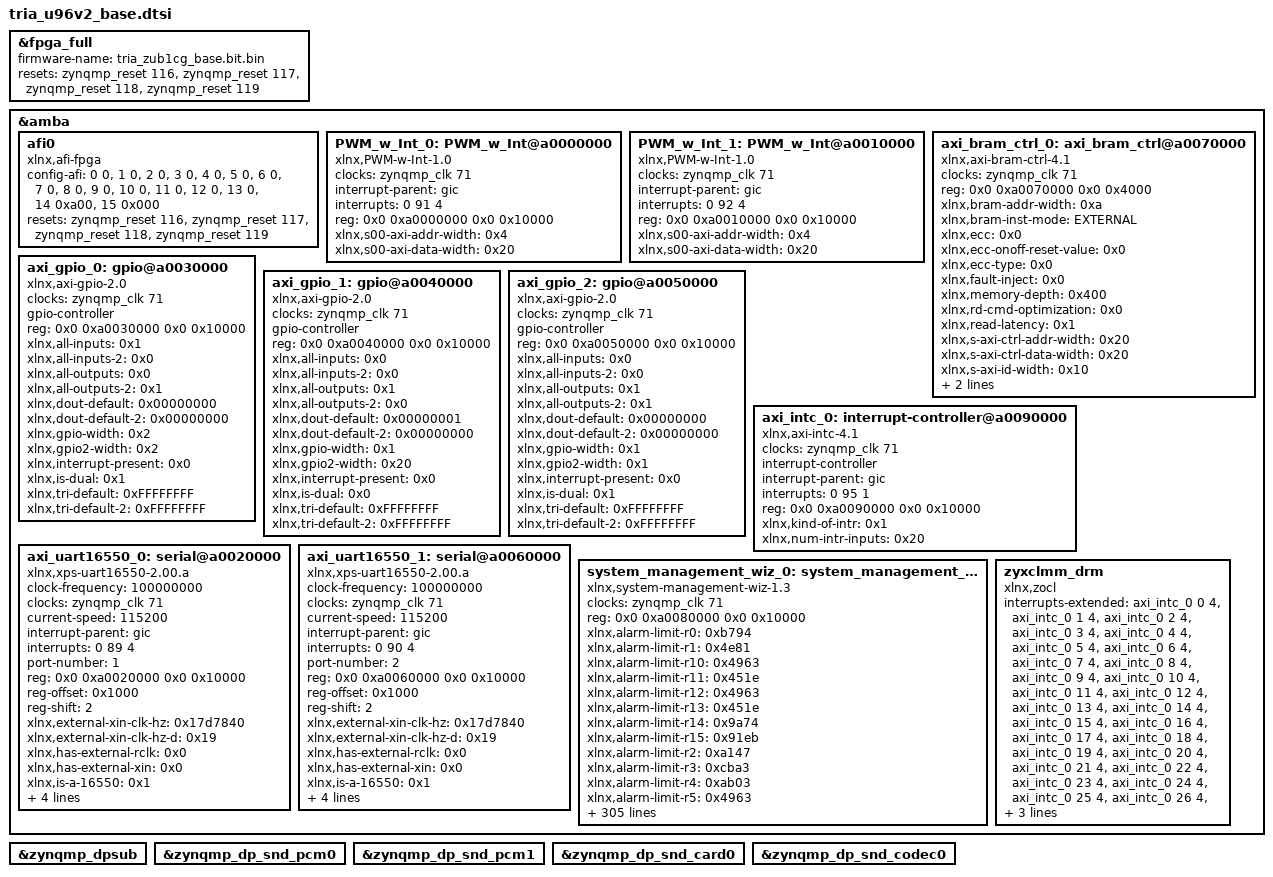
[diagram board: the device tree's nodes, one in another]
/dts-v1/;
/plugin/;

#include <dt-bindings/gpio/gpio.h>

&fpga_full {	
	#address-cells = <2>;
	#size-cells = <2>;
	firmware-name = "tria_zub1cg_base.bit.bin";
	resets = <&zynqmp_reset 116>, <&zynqmp_reset 117>, <&zynqmp_reset 118>, <&zynqmp_reset 119>;
};

&amba {
	afi0: afi0 {
		compatible = "xlnx,afi-fpga";
		config-afi = <0 0>, <1 0>, <2 0>, <3 0>, <4 0>, <5 0>, <6 0>, <7 0>, <8 0>, <9 0>, <10 0>, <11 0>, <12 0>, <13 0>, <14 0xa00>, <15 0x000>;
		resets = <&zynqmp_reset 116>, <&zynqmp_reset 117>, <&zynqmp_reset 118>, <&zynqmp_reset 119>;
		reset-names = "pl0", "pl1", "pl2", "pl3";
	};		
};

&amba {		
		PWM_w_Int_0: PWM_w_Int@a0000000 {
			clock-names = "s00_axi_aclk";
			clocks = <&zynqmp_clk 71>;
			compatible = "xlnx,PWM-w-Int-1.0";
			interrupt-names = "Interrupt_Out";
			interrupt-parent = <&gic>;
			interrupts = <0 91 4>;
			reg = <0x0 0xa0000000 0x0 0x10000>;
			xlnx,s00-axi-addr-width = <0x4>;
			xlnx,s00-axi-data-width = <0x20>;
		};
		PWM_w_Int_1: PWM_w_Int@a0010000 {
			clock-names = "s00_axi_aclk";
			clocks = <&zynqmp_clk 71>;
			compatible = "xlnx,PWM-w-Int-1.0";
			interrupt-names = "Interrupt_Out";
			interrupt-parent = <&gic>;
			interrupts = <0 92 4>;
			reg = <0x0 0xa0010000 0x0 0x10000>;
			xlnx,s00-axi-addr-width = <0x4>;
			xlnx,s00-axi-data-width = <0x20>;
		};
		axi_bram_ctrl_0: axi_bram_ctrl@a0070000 {
			clock-names = "s_axi_aclk";
			clocks = <&zynqmp_clk 71>;
			compatible = "xlnx,axi-bram-ctrl-4.1";
			reg = <0x0 0xa0070000 0x0 0x4000>;
			xlnx,bram-addr-width = <0xa>;
			xlnx,bram-inst-mode = "EXTERNAL";
			xlnx,ecc = <0x0>;
			xlnx,ecc-onoff-reset-value = <0x0>;
			xlnx,ecc-type = <0x0>;
			xlnx,fault-inject = <0x0>;
			xlnx,memory-depth = <0x400>;
			xlnx,rd-cmd-optimization = <0x0>;
			xlnx,read-latency = <0x1>;
			xlnx,s-axi-ctrl-addr-width = <0x20>;
			xlnx,s-axi-ctrl-data-width = <0x20>;
			xlnx,s-axi-id-width = <0x10>;
			xlnx,s-axi-supports-narrow-burst = <0x1>;
			xlnx,single-port-bram = <0x0>;
		};
		axi_gpio_0: gpio@a0030000 {
			#gpio-cells = <2>;
			clock-names = "s_axi_aclk";
			clocks = <&zynqmp_clk 71>;
			compatible = "xlnx,axi-gpio-2.0", "xlnx,xps-gpio-1.00.a";
			gpio-controller ;
			reg = <0x0 0xa0030000 0x0 0x10000>;
			xlnx,all-inputs = <0x1>;
			xlnx,all-inputs-2 = <0x0>;
			xlnx,all-outputs = <0x0>;
			xlnx,all-outputs-2 = <0x1>;
			xlnx,dout-default = <0x00000000>;
			xlnx,dout-default-2 = <0x00000000>;
			xlnx,gpio-width = <0x2>;
			xlnx,gpio2-width = <0x2>;
			xlnx,interrupt-present = <0x0>;
			xlnx,is-dual = <0x1>;
			xlnx,tri-default = <0xFFFFFFFF>;
			xlnx,tri-default-2 = <0xFFFFFFFF>;
		};
		axi_gpio_1: gpio@a0040000 {
			#gpio-cells = <2>;
			clock-names = "s_axi_aclk";
			clocks = <&zynqmp_clk 71>;
			compatible = "xlnx,axi-gpio-2.0", "xlnx,xps-gpio-1.00.a";
			gpio-controller ;
			reg = <0x0 0xa0040000 0x0 0x10000>;
			xlnx,all-inputs = <0x0>;
			xlnx,all-inputs-2 = <0x0>;
			xlnx,all-outputs = <0x1>;
			xlnx,all-outputs-2 = <0x0>;
			xlnx,dout-default = <0x00000001>;
			xlnx,dout-default-2 = <0x00000000>;
			xlnx,gpio-width = <0x1>;
			xlnx,gpio2-width = <0x20>;
			xlnx,interrupt-present = <0x0>;
			xlnx,is-dual = <0x0>;
			xlnx,tri-default = <0xFFFFFFFF>;
			xlnx,tri-default-2 = <0xFFFFFFFF>;
		};
		axi_gpio_2: gpio@a0050000 {
			#gpio-cells = <2>;
			clock-names = "s_axi_aclk";
			clocks = <&zynqmp_clk 71>;
			compatible = "xlnx,axi-gpio-2.0", "xlnx,xps-gpio-1.00.a";
			gpio-controller ;
			reg = <0x0 0xa0050000 0x0 0x10000>;
			xlnx,all-inputs = <0x0>;
			xlnx,all-inputs-2 = <0x0>;
			xlnx,all-outputs = <0x1>;
			xlnx,all-outputs-2 = <0x1>;
			xlnx,dout-default = <0x00000000>;
			xlnx,dout-default-2 = <0x00000000>;
			xlnx,gpio-width = <0x1>;
			xlnx,gpio2-width = <0x1>;
			xlnx,interrupt-present = <0x0>;
			xlnx,is-dual = <0x1>;
			xlnx,tri-default = <0xFFFFFFFF>;
			xlnx,tri-default-2 = <0xFFFFFFFF>;
		};
		axi_intc_0: interrupt-controller@a0090000 {
			#interrupt-cells = <2>;
			clock-names = "s_axi_aclk";
			clocks = <&zynqmp_clk 71>;
			compatible = "xlnx,axi-intc-4.1", "xlnx,xps-intc-1.00.a";
			interrupt-controller ;
			interrupt-names = "irq";
			interrupt-parent = <&gic>;
			interrupts = <0 95 1>;
			reg = <0x0 0xa0090000 0x0 0x10000>;
			xlnx,kind-of-intr = <0x1>;
			xlnx,num-intr-inputs = <0x20>;
		};
		axi_uart16550_0: serial@a0020000 {
			clock-frequency = <100000000>;
			clock-names = "s_axi_aclk";
			clocks = <&zynqmp_clk 71>;
			compatible = "xlnx,xps-uart16550-2.00.a", "ns16550a";
			current-speed = <115200>;
			device_type = "serial";
			interrupt-names = "ip2intc_irpt";
			interrupt-parent = <&gic>;
			interrupts = <0 89 4>;
			port-number = <1>;
			reg = <0x0 0xa0020000 0x0 0x10000>;
			reg-offset = <0x1000>;
			reg-shift = <2>;
			xlnx,external-xin-clk-hz = <0x17d7840>;
			xlnx,external-xin-clk-hz-d = <0x19>;
			xlnx,has-external-rclk = <0x0>;
			xlnx,has-external-xin = <0x0>;
			xlnx,is-a-16550 = <0x1>;
			xlnx,s-axi-aclk-freq-hz-d = "100.0";
			xlnx,sim-device = "VERSAL_AI_CORE_ES1";
			xlnx,use-modem-ports = <0x1>;
			xlnx,use-user-ports = <0x1>;
		};
		axi_uart16550_1: serial@a0060000 {
			clock-frequency = <100000000>;
			clock-names = "s_axi_aclk";
			clocks = <&zynqmp_clk 71>;
			compatible = "xlnx,xps-uart16550-2.00.a", "ns16550a";
			current-speed = <115200>;
			device_type = "serial";
			interrupt-names = "ip2intc_irpt";
			interrupt-parent = <&gic>;
			interrupts = <0 90 4>;
			port-number = <2>;
			reg = <0x0 0xa0060000 0x0 0x10000>;
			reg-offset = <0x1000>;
			reg-shift = <2>;
			xlnx,external-xin-clk-hz = <0x17d7840>;
			xlnx,external-xin-clk-hz-d = <0x19>;
			xlnx,has-external-rclk = <0x0>;
			xlnx,has-external-xin = <0x0>;
			xlnx,is-a-16550 = <0x1>;
			xlnx,s-axi-aclk-freq-hz-d = "100.0";
			xlnx,sim-device = "VERSAL_AI_CORE_ES1";
			xlnx,use-modem-ports = <0x1>;
			xlnx,use-user-ports = <0x1>;
		};
		system_management_wiz_0: system_management_wiz@a0080000 {
			clock-names = "s_axi_aclk";
			clocks = <&zynqmp_clk 71>;
			compatible = "xlnx,system-management-wiz-1.3";
			reg = <0x0 0xa0080000 0x0 0x10000>;
			xlnx,alarm-limit-r0 = <0xb794>;
			xlnx,alarm-limit-r1 = <0x4e81>;
			xlnx,alarm-limit-r10 = <0x4963>;
			xlnx,alarm-limit-r11 = <0x451e>;
			xlnx,alarm-limit-r12 = <0x4963>;
			xlnx,alarm-limit-r13 = <0x451e>;
			xlnx,alarm-limit-r14 = <0x9a74>;
			xlnx,alarm-limit-r15 = <0x91eb>;
			xlnx,alarm-limit-r2 = <0xa147>;
			xlnx,alarm-limit-r3 = <0xcba3>;
			xlnx,alarm-limit-r4 = <0xab03>;
			xlnx,alarm-limit-r5 = <0x4963>;
			xlnx,alarm-limit-r6 = <0x9555>;
			xlnx,alarm-limit-r7 = <0xb00a>;
			xlnx,alarm-limit-r8 = <0x4e81>;
			xlnx,alarm-limit-r9 = <0x4963>;
			xlnx,alarm-limit-slave0-ssit-usl1 = <0x4c5e>;
			xlnx,alarm-limit-slave0-ssit-usl2 = <0x4bf2>;
			xlnx,alarm-limit-slave0-ssit-usl3 = <0x98bf>;
			xlnx,alarm-limit-slave0-ssit-usl4 = <0x98bf>;
			xlnx,alarm-limit-slave0-ssit-usu1 = <0x4d39>;
			xlnx,alarm-limit-slave0-ssit-usu2 = <0x4da7>;
			xlnx,alarm-limit-slave0-ssit-usu3 = <0x9a74>;
			xlnx,alarm-limit-slave0-ssit-usu4 = <0x9a74>;
			xlnx,alarm-limit-slave1-ssit-usl1 = <0x4c5e>;
			xlnx,alarm-limit-slave1-ssit-usl2 = <0x4bf2>;
			xlnx,alarm-limit-slave1-ssit-usl3 = <0x98bf>;
			xlnx,alarm-limit-slave1-ssit-usl4 = <0x98bf>;
			xlnx,alarm-limit-slave1-ssit-usu1 = <0x4d39>;
			xlnx,alarm-limit-slave1-ssit-usu2 = <0x4da7>;
			xlnx,alarm-limit-slave1-ssit-usu3 = <0x9a74>;
			xlnx,alarm-limit-slave1-ssit-usu4 = <0x9a74>;
			xlnx,alarm-limit-slave2-ssit-usl1 = <0x4c5e>;
			xlnx,alarm-limit-slave2-ssit-usl2 = <0x4bf2>;
			xlnx,alarm-limit-slave2-ssit-usl3 = <0x98bf>;
			xlnx,alarm-limit-slave2-ssit-usl4 = <0x98bf>;
			xlnx,alarm-limit-slave2-ssit-usu1 = <0x4d39>;
			xlnx,alarm-limit-slave2-ssit-usu2 = <0x4da7>;
			xlnx,alarm-limit-slave2-ssit-usu3 = <0x9a74>;
			xlnx,alarm-limit-slave2-ssit-usu4 = <0x9a74>;
			xlnx,alarm-limit-usl1 = <0x4c5e>;
			xlnx,alarm-limit-usl2 = <0x4bf2>;
			xlnx,alarm-limit-usl3 = <0x98bf>;
			xlnx,alarm-limit-usl4 = <0x98bf>;
			xlnx,alarm-limit-usu1 = <0x4d39>;
			xlnx,alarm-limit-usu2 = <0x4da7>;
			xlnx,alarm-limit-usu3 = <0x9a74>;
			xlnx,alarm-limit-usu4 = <0x9a74>;
			xlnx,average-en-slave0-ssit-vuser0 = <0x0>;
			xlnx,average-en-slave0-ssit-vuser1 = <0x0>;
			xlnx,average-en-slave0-ssit-vuser2 = <0x0>;
			xlnx,average-en-slave0-ssit-vuser3 = <0x0>;
			xlnx,average-en-slave1-ssit-vuser0 = <0x0>;
			xlnx,average-en-slave1-ssit-vuser1 = <0x0>;
			xlnx,average-en-slave1-ssit-vuser2 = <0x0>;
			xlnx,average-en-slave1-ssit-vuser3 = <0x0>;
			xlnx,average-en-slave2-ssit-vuser0 = <0x0>;
			xlnx,average-en-slave2-ssit-vuser1 = <0x0>;
			xlnx,average-en-slave2-ssit-vuser2 = <0x0>;
			xlnx,average-en-slave2-ssit-vuser3 = <0x0>;
			xlnx,average-en-vuser0 = <0x0>;
			xlnx,average-en-vuser1 = <0x0>;
			xlnx,average-en-vuser2 = <0x0>;
			xlnx,average-en-vuser3 = <0x0>;
			xlnx,avg-slave0-ssit-vuser = <0x0>;
			xlnx,avg-slave1-ssit-vuser = <0x0>;
			xlnx,avg-slave2-ssit-vuser = <0x0>;
			xlnx,avg-vuser = <0x0>;
			xlnx,channel-cnt = <0x5>;
			xlnx,common-n-source = "Null";
			xlnx,configuration-r0 = <0x0>;
			xlnx,configuration-r1 = <0x2f9f>;
			xlnx,configuration-r2 = <0x1400>;
			xlnx,configuration-r3 = <0xf>;
			xlnx,configuration-r4 = <0x0>;
			xlnx,configuration-r4-1 = <0xc>;
			xlnx,configuration-r4-2 = <0xc>;
			xlnx,configuration-r4-3 = <0xe>;
			xlnx,configuration-r4-4 = <0xa>;
			xlnx,configuration-slave0-ssit-r3 = <0xf>;
			xlnx,configuration-slave0-ssit-r4-1 = <0xc>;
			xlnx,configuration-slave0-ssit-r4-2 = <0xc>;
			xlnx,configuration-slave0-ssit-r4-3 = <0xe>;
			xlnx,configuration-slave0-ssit-r4-4 = <0xa>;
			xlnx,configuration-slave1-ssit-r3 = <0xf>;
			xlnx,configuration-slave1-ssit-r4-1 = <0xc>;
			xlnx,configuration-slave1-ssit-r4-2 = <0xc>;
			xlnx,configuration-slave1-ssit-r4-3 = <0xe>;
			xlnx,configuration-slave1-ssit-r4-4 = <0xa>;
			xlnx,configuration-slave2-ssit-r3 = <0xf>;
			xlnx,configuration-slave2-ssit-r4-1 = <0xc>;
			xlnx,configuration-slave2-ssit-r4-2 = <0xc>;
			xlnx,configuration-slave2-ssit-r4-3 = <0xe>;
			xlnx,configuration-slave2-ssit-r4-4 = <0xa>;
			xlnx,dclk-frequency = <0x64>;
			xlnx,div-vuser0 = <0x6>;
			xlnx,div-vuser0-slave0 = <0x6>;
			xlnx,div-vuser0-slave1 = <0x6>;
			xlnx,div-vuser0-slave2 = <0x6>;
			xlnx,div-vuser1 = <0x3>;
			xlnx,div-vuser1-slave0 = <0x3>;
			xlnx,div-vuser1-slave1 = <0x3>;
			xlnx,div-vuser1-slave2 = <0x3>;
			xlnx,div-vuser2 = <0x3>;
			xlnx,div-vuser2-slave0 = <0x3>;
			xlnx,div-vuser2-slave1 = <0x3>;
			xlnx,div-vuser2-slave2 = <0x3>;
			xlnx,div-vuser3 = <0x3>;
			xlnx,div-vuser3-slave0 = <0x3>;
			xlnx,div-vuser3-slave1 = <0x3>;
			xlnx,div-vuser3-slave2 = <0x3>;
			xlnx,dual-seq = <0x0>;
			xlnx,dual-sequence-r0 = <0x0>;
			xlnx,dual-sequence-r1 = <0x0>;
			xlnx,dual-sequence-r2 = <0x0>;
			xlnx,dual0-register = <0x0>;
			xlnx,dual1-register = <0x0>;
			xlnx,dual2-register = <0x0>;
			xlnx,dual3-register = <0x0>;
			xlnx,enable-adc-data-out-master = <0x0>;
			xlnx,enable-adc-data-out-slave0 = <0x0>;
			xlnx,enable-adc-data-out-slave1 = <0x0>;
			xlnx,enable-adc-data-out-slave2 = <0x0>;
			xlnx,enable-dual-sequence-mode = <0x0>;
			xlnx,enable-slave0 = <0x0>;
			xlnx,enable-slave1 = <0x0>;
			xlnx,enable-slave2 = <0x0>;
			xlnx,external-mux-channel = "VP_VN";
			xlnx,external-muxaddr-enable = <0x0>;
			xlnx,fifo-depth = <0x7>;
			xlnx,has-axi = <0x1>;
			xlnx,has-axi4stream = <0x0>;
			xlnx,has-busy = <0x1>;
			xlnx,has-channel = <0x1>;
			xlnx,has-convst = <0x0>;
			xlnx,has-convstclk = <0x0>;
			xlnx,has-dclk = <0x1>;
			xlnx,has-drp = <0x0>;
			xlnx,has-eoc = <0x1>;
			xlnx,has-eos = <0x1>;
			xlnx,has-external-mux = <0x0>;
			xlnx,has-i2c = <0x0>;
			xlnx,has-i2c-slave = <0x0>;
			xlnx,has-jtagbusy = <0x0>;
			xlnx,has-jtaglocked = <0x0>;
			xlnx,has-jtagmodified = <0x0>;
			xlnx,has-ot-alarm = <0x0>;
			xlnx,has-pmbus = <0x0>;
			xlnx,has-pmc = <0x0>;
			xlnx,has-pmc-master = <0x0>;
			xlnx,has-reset = <0x0>;
			xlnx,has-slave0-ssit-temp-ch = <0x1>;
			xlnx,has-slave0-ssit-vuser0 = <0x0>;
			xlnx,has-slave0-ssit-vuser1 = <0x0>;
			xlnx,has-slave0-ssit-vuser2 = <0x0>;
			xlnx,has-slave0-ssit-vuser3 = <0x0>;
			xlnx,has-slave1-ssit-temp-ch = <0x1>;
			xlnx,has-slave1-ssit-vuser0 = <0x0>;
			xlnx,has-slave1-ssit-vuser1 = <0x0>;
			xlnx,has-slave1-ssit-vuser2 = <0x0>;
			xlnx,has-slave1-ssit-vuser3 = <0x0>;
			xlnx,has-slave2-ssit-temp-ch = <0x1>;
			xlnx,has-slave2-ssit-vuser0 = <0x0>;
			xlnx,has-slave2-ssit-vuser1 = <0x0>;
			xlnx,has-slave2-ssit-vuser2 = <0x0>;
			xlnx,has-slave2-ssit-vuser3 = <0x0>;
			xlnx,has-temp-bus = <0x0>;
			xlnx,has-under-ot-alarm = <0x0>;
			xlnx,has-under-temp-alarm = <0x0>;
			xlnx,has-user-supply0-alarm = <0x0>;
			xlnx,has-user-supply0-slave0-ssit-alarm = <0x0>;
			xlnx,has-user-supply0-slave1-ssit-alarm = <0x0>;
			xlnx,has-user-supply0-slave2-ssit-alarm = <0x0>;
			xlnx,has-user-supply1-alarm = <0x0>;
			xlnx,has-user-supply1-slave0-ssit-alarm = <0x0>;
			xlnx,has-user-supply1-slave1-ssit-alarm = <0x0>;
			xlnx,has-user-supply1-slave2-ssit-alarm = <0x0>;
			xlnx,has-user-supply2-alarm = <0x0>;
			xlnx,has-user-supply2-slave0-ssit-alarm = <0x0>;
			xlnx,has-user-supply2-slave1-ssit-alarm = <0x0>;
			xlnx,has-user-supply2-slave2-ssit-alarm = <0x0>;
			xlnx,has-user-supply3-alarm = <0x0>;
			xlnx,has-user-supply3-slave0-ssit-alarm = <0x0>;
			xlnx,has-user-supply3-slave1-ssit-alarm = <0x0>;
			xlnx,has-user-supply3-slave2-ssit-alarm = <0x0>;
			xlnx,has-user-temp-alarm = <0x0>;
			xlnx,has-vbram-alarm = <0x0>;
			xlnx,has-vccaux-alarm = <0x0>;
			xlnx,has-vccddro-alarm = <0x0>;
			xlnx,has-vccint-alarm = <0x0>;
			xlnx,has-vccpaux-alarm = <0x0>;
			xlnx,has-vccpint-alarm = <0x0>;
			xlnx,has-vccpsaux-alarm = <0x0>;
			xlnx,has-vccpsintfp-alarm = <0x0>;
			xlnx,has-vccpsintlp-alarm = <0x0>;
			xlnx,has-vn = <0x1>;
			xlnx,has-vp = <0x1>;
			xlnx,has-vuser0 = <0x0>;
			xlnx,has-vuser1 = <0x0>;
			xlnx,has-vuser2 = <0x0>;
			xlnx,has-vuser3 = <0x0>;
			xlnx,i2c-clk-period = "2500.000";
			xlnx,i2c-sclk-loc = "F3";
			xlnx,i2c-sda-loc = "D2";
			xlnx,i2c-slave-address = <0x20>;
			xlnx,i2c-slave0-address = <0x20>;
			xlnx,i2c-slave1-address = <0x20>;
			xlnx,i2c-slave2-address = <0x20>;
			xlnx,include-intr = <0x1>;
			xlnx,is-diablo = <0x1>;
			xlnx,is-ssit-slave0 = <0x0>;
			xlnx,is-ssit-slave0-analog-bank = <0x0>;
			xlnx,is-ssit-slave1 = <0x0>;
			xlnx,is-ssit-slave1-analog-bank = <0x0>;
			xlnx,is-ssit-slave2 = <0x0>;
			xlnx,is-ssit-slave2-analog-bank = <0x0>;
			xlnx,sampling-rate = "192307.6923076923";
			xlnx,sequence-r0 = <0x4701>;
			xlnx,sequence-r1 = <0x0>;
			xlnx,sequence-r2 = <0x0>;
			xlnx,sequence-r3 = <0x0>;
			xlnx,sequence-r4 = <0x0>;
			xlnx,sequence-r5 = <0x0>;
			xlnx,sequence-r6 = <0x0>;
			xlnx,sequence-r7 = <0x0>;
			xlnx,sequence-r8 = <0x0>;
			xlnx,sequence-slave0-ssit-r0 = <0x100>;
			xlnx,sequence-slave0-ssit-r8 = <0x0>;
			xlnx,sequence-slave1-ssit-r0 = <0x100>;
			xlnx,sequence-slave1-ssit-r8 = <0x0>;
			xlnx,sequence-slave2-ssit-r0 = <0x100>;
			xlnx,sequence-slave2-ssit-r8 = <0x0>;
			xlnx,sim-device = "ZYNQ_ULTRASCALE";
			xlnx,sim-file-name = "design";
			xlnx,sim-file-rel-path = "./";
			xlnx,sim-file-sel = "Default";
			xlnx,user-supply0-bank = <0x2c>;
			xlnx,user-supply0-slave0-ssit-bank = <0x2c>;
			xlnx,user-supply0-slave0-ssit-source = "VCCO";
			xlnx,user-supply0-slave1-ssit-bank = <0x2c>;
			xlnx,user-supply0-slave1-ssit-source = "VCCO";
			xlnx,user-supply0-slave2-ssit-bank = <0x2c>;
			xlnx,user-supply0-slave2-ssit-source = "VCCO";
			xlnx,user-supply0-source = "VCCO";
			xlnx,user-supply1-bank = <0x2c>;
			xlnx,user-supply1-slave0-ssit-bank = <0x2c>;
			xlnx,user-supply1-slave0-ssit-source = "VCCINT";
			xlnx,user-supply1-slave1-ssit-bank = <0x2c>;
			xlnx,user-supply1-slave1-ssit-source = "VCCINT";
			xlnx,user-supply1-slave2-ssit-bank = <0x2c>;
			xlnx,user-supply1-slave2-ssit-source = "VCCINT";
			xlnx,user-supply1-source = "VCCINT";
			xlnx,user-supply2-bank = <0x2c>;
			xlnx,user-supply2-slave0-ssit-bank = <0x2c>;
			xlnx,user-supply2-slave0-ssit-source = "VCCAUX";
			xlnx,user-supply2-slave1-ssit-bank = <0x2c>;
			xlnx,user-supply2-slave1-ssit-source = "VCCAUX";
			xlnx,user-supply2-slave2-ssit-bank = <0x2c>;
			xlnx,user-supply2-slave2-ssit-source = "VCCAUX";
			xlnx,user-supply2-source = "VCCAUX";
			xlnx,user-supply3-bank = <0x41>;
			xlnx,user-supply3-slave0-ssit-bank = <0x41>;
			xlnx,user-supply3-slave0-ssit-source = "VCCO";
			xlnx,user-supply3-slave1-ssit-bank = <0x41>;
			xlnx,user-supply3-slave1-ssit-source = "VCCO";
			xlnx,user-supply3-slave2-ssit-bank = <0x41>;
			xlnx,user-supply3-slave2-ssit-source = "VCCO";
			xlnx,user-supply3-source = "VCCO";
			xlnx,vaux0 = <0x0>;
			xlnx,vaux1 = <0x0>;
			xlnx,vaux10 = <0x0>;
			xlnx,vaux11 = <0x0>;
			xlnx,vaux12 = <0x0>;
			xlnx,vaux13 = <0x0>;
			xlnx,vaux14 = <0x0>;
			xlnx,vaux15 = <0x0>;
			xlnx,vaux2 = <0x0>;
			xlnx,vaux3 = <0x0>;
			xlnx,vaux4 = <0x0>;
			xlnx,vaux5 = <0x0>;
			xlnx,vaux6 = <0x0>;
			xlnx,vaux7 = <0x0>;
			xlnx,vaux8 = <0x0>;
			xlnx,vaux9 = <0x0>;
			xlnx,vauxn0-loc = "C3";
			xlnx,vauxn1-loc = "E3";
			xlnx,vauxn10-loc = "G2";
			xlnx,vauxn11-loc = "J1";
			xlnx,vauxn12-loc = "M1";
			xlnx,vauxn13-loc = "P1";
			xlnx,vauxn14-loc = "T1";
			xlnx,vauxn15-loc = "U1";
			xlnx,vauxn2-loc = "G4";
			xlnx,vauxn3-loc = "H5";
			xlnx,vauxn4-loc = "M4";
			xlnx,vauxn5-loc = "N4";
			xlnx,vauxn6-loc = "R5";
			xlnx,vauxn7-loc = "T4";
			xlnx,vauxn8-loc = "D1";
			xlnx,vauxn9-loc = "F1";
			xlnx,vauxp0-loc = "D3";
			xlnx,vauxp1-loc = "E4";
			xlnx,vauxp10-loc = "H2";
			xlnx,vauxp11-loc = "K1";
			xlnx,vauxp12-loc = "M2";
			xlnx,vauxp13-loc = "N2";
			xlnx,vauxp14-loc = "R1";
			xlnx,vauxp15-loc = "U2";
			xlnx,vauxp2-loc = "H4";
			xlnx,vauxp3-loc = "J5";
			xlnx,vauxp4-loc = "M5";
			xlnx,vauxp5-loc = "N5";
			xlnx,vauxp6-loc = "P5";
			xlnx,vauxp7-loc = "R4";
			xlnx,vauxp8-loc = "E1";
			xlnx,vauxp9-loc = "G1";
			xlnx,vpvn = <0x0>;
		};
		zyxclmm_drm {
			compatible = "xlnx,zocl";
			interrupts-extended = <&axi_intc_0 0 4>, <&axi_intc_0 1 4>, <&axi_intc_0 2 4>, <&axi_intc_0 3 4>, <&axi_intc_0 4 4>, <&axi_intc_0 5 4>, <&axi_intc_0 6 4>, <&axi_intc_0 7 4>, <&axi_intc_0 8 4>, <&axi_intc_0 9 4>,
<&axi_intc_0 10 4>, <&axi_intc_0 11 4>, <&axi_intc_0 12 4>, <&axi_intc_0 13 4>, <&axi_intc_0 14 4>,
<&axi_intc_0 15 4>, <&axi_intc_0 16 4>, <&axi_intc_0 17 4>, <&axi_intc_0 18 4>, <&axi_intc_0 19 4>,
<&axi_intc_0 20 4>, <&axi_intc_0 21 4>, <&axi_intc_0 22 4>, <&axi_intc_0 23 4>, <&axi_intc_0 24 4>,
<&axi_intc_0 25 4>, <&axi_intc_0 26 4>, <&axi_intc_0 27 4>, <&axi_intc_0 28 4>, <&axi_intc_0 29 4>,
<&axi_intc_0 30 4>, <&axi_intc_0 31 4 >;
		};
};

&zynqmp_dpsub {
	status = "okay";		
};
&zynqmp_dp_snd_pcm0 {
	status = "okay";		
};
&zynqmp_dp_snd_pcm1 {
	status = "okay";		
};
&zynqmp_dp_snd_card0 {
	status = "okay";		
};
&zynqmp_dp_snd_codec0 {
	status = "okay";		
};

